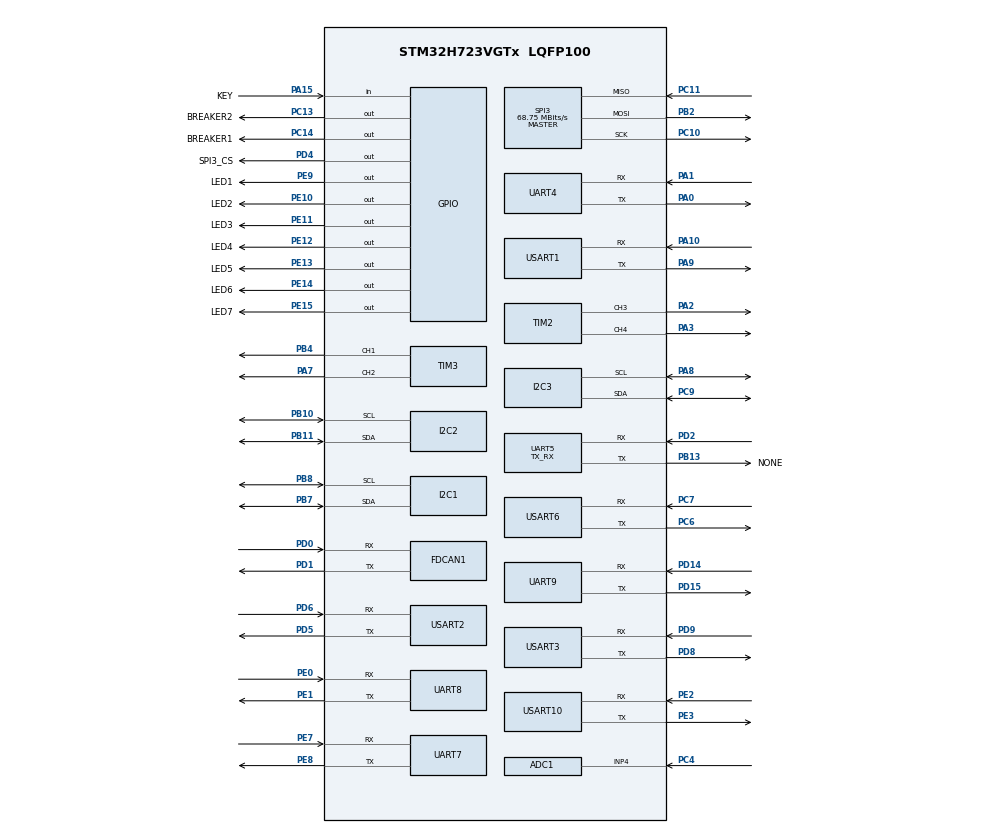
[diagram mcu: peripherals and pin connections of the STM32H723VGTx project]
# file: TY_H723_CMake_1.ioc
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ADC1.Channel-0\#ChannelRegularConversion=ADC_CHANNEL_4
ADC1.NbrOfConversionFlag=1
ADC1.OffsetNumber-0\#ChannelRegularConversion=ADC_OFFSET_NONE
ADC1.OffsetSignedSaturation-0\#ChannelRegularConversion=DISABLE
ADC1.Rank-0\#ChannelRegularConversion=1
ADC1.SamplingTime-0\#ChannelRegularConversion=ADC_SAMPLETIME_1CYCLE_5
ADC1.master=1
CORTEX_M7.MPU_Control=__NULL
CORTEX_M7.default_mode_Activation=0
Dma.Request0=USART1_TX
Dma.Request1=USART6_TX
Dma.Request2=USART1_RX
Dma.Request3=USART6_RX
Dma.Request4=UART9_RX
Dma.Request5=UART9_TX
Dma.UART9_RX.4.Direction=DMA_PERIPH_TO_MEMORY
Dma.UART9_RX.4.EventEnable=DISABLE
Dma.UART9_RX.4.FIFOMode=DMA_FIFOMODE_DISABLE
Dma.UART9_RX.4.Instance=DMA1_Stream4
Dma.UART9_RX.4.MemDataAlignment=DMA_MDATAALIGN_BYTE
Dma.UART9_RX.4.MemInc=DMA_MINC_ENABLE
Dma.UART9_RX.4.Mode=DMA_NORMAL
Dma.UART9_RX.4.PeriphDataAlignment=DMA_PDATAALIGN_BYTE
Dma.UART9_RX.4.PeriphInc=DMA_PINC_DISABLE
Dma.UART9_RX.4.Polarity=HAL_DMAMUX_REQ_GEN_RISING
Dma.UART9_RX.4.Priority=DMA_PRIORITY_LOW
Dma.UART9_RX.4.RequestNumber=1
Dma.UART9_RX.4.SignalID=NONE
Dma.UART9_RX.4.SyncEnable=DISABLE
Dma.UART9_RX.4.SyncPolarity=HAL_DMAMUX_SYNC_NO_EVENT
Dma.UART9_RX.4.SyncRequestNumber=1
Dma.UART9_RX.4.SyncSignalID=NONE
Dma.UART9_TX.5.Direction=DMA_MEMORY_TO_PERIPH
Dma.UART9_TX.5.EventEnable=DISABLE
Dma.UART9_TX.5.FIFOMode=DMA_FIFOMODE_ENABLE
Dma.UART9_TX.5.FIFOThreshold=DMA_FIFO_THRESHOLD_FULL
Dma.UART9_TX.5.Instance=DMA1_Stream5
Dma.UART9_TX.5.MemBurst=DMA_MBURST_SINGLE
Dma.UART9_TX.5.MemDataAlignment=DMA_MDATAALIGN_BYTE
Dma.UART9_TX.5.MemInc=DMA_MINC_ENABLE
Dma.UART9_TX.5.Mode=DMA_NORMAL
Dma.UART9_TX.5.PeriphBurst=DMA_PBURST_SINGLE
Dma.UART9_TX.5.PeriphDataAlignment=DMA_PDATAALIGN_BYTE
Dma.UART9_TX.5.PeriphInc=DMA_PINC_DISABLE
Dma.UART9_TX.5.Polarity=HAL_DMAMUX_REQ_GEN_RISING
Dma.UART9_TX.5.Priority=DMA_PRIORITY_LOW
Dma.UART9_TX.5.RequestNumber=1
Dma.UART9_TX.5.SignalID=NONE
Dma.UART9_TX.5.SyncEnable=DISABLE
Dma.UART9_TX.5.SyncPolarity=HAL_DMAMUX_SYNC_NO_EVENT
Dma.UART9_TX.5.SyncRequestNumber=1
Dma.UART9_TX.5.SyncSignalID=NONE
Dma.USART1_RX.2.Direction=DMA_PERIPH_TO_MEMORY
Dma.USART1_RX.2.EventEnable=DISABLE
Dma.USART1_RX.2.FIFOMode=DMA_FIFOMODE_ENABLE
Dma.USART1_RX.2.FIFOThreshold=DMA_FIFO_THRESHOLD_FULL
Dma.USART1_RX.2.Instance=DMA1_Stream1
Dma.USART1_RX.2.MemBurst=DMA_MBURST_SINGLE
Dma.USART1_RX.2.MemDataAlignment=DMA_MDATAALIGN_BYTE
Dma.USART1_RX.2.MemInc=DMA_MINC_ENABLE
Dma.USART1_RX.2.Mode=DMA_NORMAL
Dma.USART1_RX.2.PeriphBurst=DMA_PBURST_SINGLE
Dma.USART1_RX.2.PeriphDataAlignment=DMA_PDATAALIGN_BYTE
Dma.USART1_RX.2.PeriphInc=DMA_PINC_DISABLE
Dma.USART1_RX.2.Polarity=HAL_DMAMUX_REQ_GEN_RISING
Dma.USART1_RX.2.Priority=DMA_PRIORITY_LOW
Dma.USART1_RX.2.RequestNumber=1
Dma.USART1_RX.2.SignalID=NONE
Dma.USART1_RX.2.SyncEnable=DISABLE
Dma.USART1_RX.2.SyncPolarity=HAL_DMAMUX_SYNC_NO_EVENT
Dma.USART1_RX.2.SyncRequestNumber=1
Dma.USART1_RX.2.SyncSignalID=NONE
Dma.USART1_TX.0.Direction=DMA_MEMORY_TO_PERIPH
Dma.USART1_TX.0.EventEnable=DISABLE
Dma.USART1_TX.0.FIFOMode=DMA_FIFOMODE_ENABLE
Dma.USART1_TX.0.FIFOThreshold=DMA_FIFO_THRESHOLD_FULL
Dma.USART1_TX.0.Instance=DMA1_Stream3
Dma.USART1_TX.0.MemBurst=DMA_MBURST_SINGLE
Dma.USART1_TX.0.MemDataAlignment=DMA_MDATAALIGN_BYTE
Dma.USART1_TX.0.MemInc=DMA_MINC_ENABLE
Dma.USART1_TX.0.Mode=DMA_NORMAL
Dma.USART1_TX.0.PeriphBurst=DMA_PBURST_SINGLE
Dma.USART1_TX.0.PeriphDataAlignment=DMA_PDATAALIGN_BYTE
Dma.USART1_TX.0.PeriphInc=DMA_PINC_DISABLE
Dma.USART1_TX.0.Polarity=HAL_DMAMUX_REQ_GEN_RISING
Dma.USART1_TX.0.Priority=DMA_PRIORITY_LOW
Dma.USART1_TX.0.RequestNumber=1
Dma.USART1_TX.0.SignalID=NONE
Dma.USART1_TX.0.SyncEnable=DISABLE
Dma.USART1_TX.0.SyncPolarity=HAL_DMAMUX_SYNC_NO_EVENT
Dma.USART1_TX.0.SyncRequestNumber=1
Dma.USART1_TX.0.SyncSignalID=NONE
Dma.USART6_RX.3.Direction=DMA_PERIPH_TO_MEMORY
Dma.USART6_RX.3.EventEnable=DISABLE
Dma.USART6_RX.3.FIFOMode=DMA_FIFOMODE_DISABLE
Dma.USART6_RX.3.Instance=DMA1_Stream0
Dma.USART6_RX.3.MemDataAlignment=DMA_MDATAALIGN_BYTE
Dma.USART6_RX.3.MemInc=DMA_MINC_ENABLE
Dma.USART6_RX.3.Mode=DMA_NORMAL
Dma.USART6_RX.3.PeriphDataAlignment=DMA_PDATAALIGN_BYTE
Dma.USART6_RX.3.PeriphInc=DMA_PINC_DISABLE
Dma.USART6_RX.3.Polarity=HAL_DMAMUX_REQ_GEN_RISING
Dma.USART6_RX.3.Priority=DMA_PRIORITY_LOW
Dma.USART6_RX.3.RequestNumber=1
Dma.USART6_RX.3.SignalID=NONE
Dma.USART6_RX.3.SyncEnable=DISABLE
Dma.USART6_RX.3.SyncPolarity=HAL_DMAMUX_SYNC_NO_EVENT
Dma.USART6_RX.3.SyncRequestNumber=1
Dma.USART6_RX.3.SyncSignalID=NONE
Dma.USART6_TX.1.Direction=DMA_MEMORY_TO_PERIPH
Dma.USART6_TX.1.EventEnable=DISABLE
Dma.USART6_TX.1.FIFOMode=DMA_FIFOMODE_ENABLE
Dma.USART6_TX.1.FIFOThreshold=DMA_FIFO_THRESHOLD_FULL
Dma.USART6_TX.1.Instance=DMA1_Stream2
Dma.USART6_TX.1.MemBurst=DMA_MBURST_SINGLE
Dma.USART6_TX.1.MemDataAlignment=DMA_MDATAALIGN_BYTE
Dma.USART6_TX.1.MemInc=DMA_MINC_ENABLE
Dma.USART6_TX.1.Mode=DMA_NORMAL
Dma.USART6_TX.1.PeriphBurst=DMA_PBURST_SINGLE
Dma.USART6_TX.1.PeriphDataAlignment=DMA_PDATAALIGN_BYTE
Dma.USART6_TX.1.PeriphInc=DMA_PINC_DISABLE
Dma.USART6_TX.1.Polarity=HAL_DMAMUX_REQ_GEN_RISING
Dma.USART6_TX.1.Priority=DMA_PRIORITY_LOW
Dma.USART6_TX.1.RequestNumber=1
Dma.USART6_TX.1.SignalID=NONE
Dma.USART6_TX.1.SyncEnable=DISABLE
Dma.USART6_TX.1.SyncPolarity=HAL_DMAMUX_SYNC_NO_EVENT
Dma.USART6_TX.1.SyncRequestNumber=1
Dma.USART6_TX.1.SyncSignalID=NONE
FDCAN1.AutoRetransmission=ENABLE
FDCAN1.CalculateBaudRateNominal=1000000
FDCAN1.CalculateTimeBitNominal=1000
FDCAN1.CalculateTimeQuantumNominal=62.5
FDCAN1.NominalPrescaler=6
FDCAN1.NominalTimeSeg1=11
FDCAN1.NominalTimeSeg2=4
FDCAN1.RxBuffersNbr=0
FDCAN1.RxFifo0ElmtsNbr=4
FDCAN1.RxFifo1ElmtsNbr=0
FDCAN1.StdFiltersNbr=4
FDCAN1.TxFifoQueueElmtsNbr=32
FREERTOS.Tasks01=defaultTask,24,128,_defaultTask,As weak,NULL,Dynamic,NULL,NULL
FREERTOS.configENABLE_FPU=1
FREERTOS.configUSE_NEWLIB_REENTRANT=1
I2C1.Timing=0x60404E72
I2C2.Timing=0x60404E72
I2C3.Timing=0x60404E72
Mcu.Family=STM32H7
Mcu.Name=STM32H723VGTx
Mcu.Package=LQFP100
NVIC.DMA1_Stream0_IRQn=true\:5\:0\:false\:false\:true\:true\:false\:true\:true
NVIC.DMA1_Stream1_IRQn=true\:5\:0\:false\:false\:true\:true\:false\:true\:true
NVIC.DMA1_Stream2_IRQn=true\:5\:0\:false\:false\:true\:true\:false\:true\:true
NVIC.DMA1_Stream3_IRQn=true\:5\:0\:false\:false\:true\:true\:false\:true\:true
NVIC.DMA1_Stream4_IRQn=true\:5\:0\:false\:false\:true\:true\:false\:true\:true
NVIC.DMA1_Stream5_IRQn=true\:5\:0\:false\:false\:true\:true\:false\:true\:true
NVIC.FDCAN1_IT0_IRQn=true\:5\:0\:false\:false\:true\:true\:true\:true\:true
NVIC.PriorityGroup=NVIC_PRIORITYGROUP_4
NVIC.TIM1_UP_IRQn=true\:15\:0\:false\:false\:true\:false\:false\:true\:true
NVIC.TimeBase=TIM1_UP_IRQn
NVIC.TimeBaseIP=TIM1
NVIC.UART9_IRQn=true\:5\:0\:false\:false\:true\:true\:true\:true\:true
NVIC.USART1_IRQn=true\:5\:0\:false\:false\:true\:true\:true\:true\:true
NVIC.USART6_IRQn=true\:5\:0\:false\:false\:true\:true\:true\:true\:true
PA0.Mode=Asynchronous
PA0.Signal=UART4_TX
PA1.Mode=Asynchronous
PA1.Signal=UART4_RX
PA10.Mode=Asynchronous
PA10.Signal=USART1_RX
PA13(JTMS/SWDIO).Mode=Serial_Wire
PA13(JTMS/SWDIO).Signal=DEBUG_JTMS-SWDIO
PA14(JTCK/SWCLK).Mode=Serial_Wire
PA14(JTCK/SWCLK).Signal=DEBUG_JTCK-SWCLK
PA15(JTDI).GPIO_Label=KEY
PA15(JTDI).Signal=GPIO_Input
PA2.Signal=S_TIM2_CH3
PA3.Signal=S_TIM2_CH4
PA7.Signal=S_TIM3_CH2
PA8.Mode=I2C
PA8.Signal=I2C3_SCL
PA9.Mode=Asynchronous
PA9.Signal=USART1_TX
PB10.Mode=I2C
PB10.Signal=I2C2_SCL
PB11.Mode=I2C
PB11.Signal=I2C2_SDA
PB13.GPIO_Label=NONE
PB13.Mode=Asynchronous
PB13.Signal=UART5_TX
PB13.Stacked=true
PB2.Mode=Full_Duplex_Master
PB2.Signal=SPI3_MOSI
PB4(NJTRST).Signal=S_TIM3_CH1
PB5.Signal=FDCAN2_RX
PB6.Signal=FDCAN2_TX
PB7.Mode=I2C
PB7.Signal=I2C1_SDA
PB8.Mode=I2C
PB8.Signal=I2C1_SCL
PC10.Mode=Full_Duplex_Master
PC10.Signal=SPI3_SCK
PC11.Mode=Full_Duplex_Master
PC11.Signal=SPI3_MISO
PC13.GPIO_Label=BREAKER2
PC13.Signal=GPIO_Output
PC14-OSC32_IN.GPIO_Label=BREAKER1
PC14-OSC32_IN.Signal=GPIO_Output
PC4.Signal=ADCx_INP4
PC6.Mode=Asynchronous
PC6.Signal=USART6_TX
PC7.Mode=Asynchronous
PC7.Signal=USART6_RX
PC9.Mode=I2C
PC9.Signal=I2C3_SDA
PD0.Mode=FDCAN_Activate
PD0.Signal=FDCAN1_RX
PD1.Mode=FDCAN_Activate
PD1.Signal=FDCAN1_TX
PD12.Signal=FDCAN3_RX
PD13.Signal=FDCAN3_TX
PD14.Mode=Asynchronous
PD14.Signal=UART9_RX
PD15.Mode=Asynchronous
PD15.Signal=UART9_TX
PD2.Mode=Asynchronous
PD2.Signal=UART5_RX
PD4.GPIO_Label=SPI3_CS
PD4.Signal=GPIO_Output
PD5.Mode=Asynchronous
PD5.Signal=USART2_TX
PD6.Mode=Asynchronous
PD6.Signal=USART2_RX
PD8.Mode=Asynchronous
PD8.Signal=USART3_TX
PD9.Mode=Asynchronous
PD9.Signal=USART3_RX
PE0.Mode=Asynchronous
PE0.Signal=UART8_RX
PE1.Mode=Asynchronous
PE1.Signal=UART8_TX
PE10.GPIO_Label=LED2
PE10.Signal=GPIO_Output
PE11.GPIO_Label=LED3
PE11.Signal=GPIO_Output
PE12.GPIO_Label=LED4
PE12.Signal=GPIO_Output
PE13.GPIO_Label=LED5
PE13.Signal=GPIO_Output
PE14.GPIO_Label=LED6
PE14.Signal=GPIO_Output
PE15.GPIO_Label=LED7
PE15.Signal=GPIO_Output
PE2.Mode=Asynchronous
PE2.Signal=USART10_RX
PE3.Mode=Asynchronous
PE3.Signal=USART10_TX
PE7.Mode=Asynchronous
PE7.Signal=UART7_RX
PE8.Mode=Asynchronous
PE8.Signal=UART7_TX
PE9.GPIO_Label=LED1
PE9.Signal=GPIO_Output
PH0-OSC_IN.Mode=HSE-External-Oscillator
PH0-OSC_IN.Signal=RCC_OSC_IN
PH1-OSC_OUT.Mode=HSE-External-Oscillator
PH1-OSC_OUT.Signal=RCC_OSC_OUT
ProjectManager.HeapSize=0x400
ProjectManager.StackSize=0x400
ProjectManager.TargetToolchain=CMake
RCC.ADCFreq_Value=96000000
RCC.APB1Freq_Value=137500000
RCC.APB2Freq_Value=137500000
RCC.APB3Freq_Value=137500000
RCC.APB4Freq_Value=137500000
RCC.CortexFreq_Value=550000000
RCC.D1PPRE=RCC_APB3_DIV2
RCC.D2PPRE1=RCC_APB1_DIV2
RCC.D2PPRE2=RCC_APB2_DIV2
RCC.D3PPRE=RCC_APB4_DIV2
RCC.DIVM1=4
RCC.DIVM2=4
RCC.DIVN1=34
RCC.DIVN2=12
RCC.DIVP1=1
RCC.DIVQ1=4
RCC.FDCANCLockSelection=RCC_FDCANCLKSOURCE_PLL2
RCC.HCLKFreq_Value=275000000
RCC.HPRE=RCC_HCLK_DIV2
RCC.HSE_VALUE=24000000
RCC.PLL1_VCI_Range-AdvancedSettings=RCC_PLL1VCIRANGE_0
RCC.PLL1_VCO_SEL-AdvancedSettings=RCC_PLL1VCOMEDIUM
RCC.PLL2FRACN=0
RCC.PLL2_VCI_Range-AdvancedSettings=RCC_PLL2VCIRANGE_0
RCC.PLL2_VCO_SEL-AdvancedSettings=RCC_PLL2VCOMEDIUM
RCC.PLL3FRACN=0
RCC.PLL3_VCI_Range-AdvancedSettings=RCC_PLL3VCIRANGE_1
RCC.PLL3_VCO_SEL-AdvancedSettings=RCC_PLL3VCOWIDE
RCC.PLLFRACN=3072
RCC.SYSCLKFreq_VALUE=550000000
RCC.SYSCLKSource=RCC_SYSCLKSOURCE_PLLCLK
RCC.USBFreq_Value=137500000
SH.ADCx_INP4.0=ADC1_INP4,IN4-Single-Ended
SH.S_TIM2_CH3.0=TIM2_CH3,PWM Generation3 CH3
SH.S_TIM2_CH4.0=TIM2_CH4,PWM Generation4 CH4
SH.S_TIM3_CH1.0=TIM3_CH1,PWM Generation1 CH1
SH.S_TIM3_CH2.0=TIM3_CH2,PWM Generation2 CH2
SPI3.CalculateBaudRate=68.75 MBits/s
SPI3.Direction=SPI_DIRECTION_2LINES
SPI3.Mode=SPI_MODE_MASTER
SPI3.VirtualType=VM_MASTER
TIM2.Channel-PWM\ Generation3\ CH3=TIM_CHANNEL_3
TIM2.Channel-PWM\ Generation4\ CH4=TIM_CHANNEL_4
TIM3.Channel-PWM\ Generation1\ CH1=TIM_CHANNEL_1
TIM3.Channel-PWM\ Generation2\ CH2=TIM_CHANNEL_2
UART5.Mode=MODE_TX_RX
USART1.VirtualMode-Asynchronous=VM_ASYNC
USART10.VirtualMode=VM_ASYNC
USART2.FIFOMode=FIFOMODE_DISABLE
USART2.VirtualMode-Asynchronous=VM_ASYNC
USART3.VirtualMode-Asynchronous=VM_ASYNC
USART6.VirtualMode=VM_ASYNC
VP_FREERTOS_VS_CMSIS_V2.Mode=CMSIS_V2
VP_MEMORYMAP_VS_MEMORYMAP.Mode=CurAppReg
VP_SYS_VS_tim1.Mode=TIM1
board=custom

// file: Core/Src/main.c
/* USER CODE BEGIN Header */
/**
  ******************************************************************************
  * @file           : main.c
  * @brief          : Main program body
  ******************************************************************************
  * @attention
  *
  * Copyright (c) 2026 STMicroelectronics.
  * All rights reserved.
  *
  * This software is licensed under terms that can be found in the LICENSE file
  * in the root directory of this software component.
  * If no LICENSE file comes with this software, it is provided AS-IS.
  *
  ******************************************************************************
  */
/* USER CODE END Header */
#include "main.h"
#include "FreeRTOS.h"
#include "cmsis_os2.h"
#include "adc.h"
#include "dma.h"
#include "fdcan.h"
#include "i2c.h"
#include "spi.h"
#include "tim.h"
#include "usart.h"
#include "gpio.h"

/* USER CODE BEGIN Includes */
#include "api_main.h"
/* USER CODE END Includes */

void SystemClock_Config(void);
void PeriphCommonClock_Config(void);
void MX_FREERTOS_Init(void);

int main(void)
{

  /* MCU Configuration--------------------------------------------------------*/

  /* Reset of all peripherals, Initializes the Flash interface and the Systick. */
  HAL_Init();

  /* Configure the system clock */
  SystemClock_Config();

  /* Configure the peripherals common clocks */
  PeriphCommonClock_Config();

  /* Initialize all configured peripherals */
  MX_GPIO_Init();
  MX_DMA_Init();
  MX_ADC1_Init();
  MX_FDCAN1_Init();
  MX_I2C1_Init();
  MX_I2C2_Init();
  MX_I2C3_Init();
  MX_SPI3_Init();
  MX_TIM2_Init();
  MX_TIM3_Init();
  MX_UART4_Init();
  MX_UART5_Init();
  MX_UART7_Init();
  MX_UART8_Init();
  MX_UART9_Init();
  MX_USART1_UART_Init();
  MX_USART2_UART_Init();
  MX_USART3_UART_Init();
  MX_USART6_UART_Init();
  MX_USART10_UART_Init();
  /* USER CODE BEGIN 2 */
  app_init();
  /* USER CODE END 2 */

  /* Init scheduler */
  osKernelInitialize();  /* Call init function for freertos objects (in cmsis_os2.c) */
  MX_FREERTOS_Init();

  /* Start scheduler */
  osKernelStart();

  /* We should never get here as control is now taken by the scheduler */

  /* Infinite loop */
  while (1)
  {

  }
}

void SystemClock_Config(void)
{
  RCC_OscInitTypeDef RCC_OscInitStruct = {0};
  RCC_ClkInitTypeDef RCC_ClkInitStruct = {0};

  /** Supply configuration update enable
  */
  HAL_PWREx_ConfigSupply(PWR_LDO_SUPPLY);

  /** Configure the main internal regulator output voltage
  */
  __HAL_PWR_VOLTAGESCALING_CONFIG(PWR_REGULATOR_VOLTAGE_SCALE0);

  while(!__HAL_PWR_GET_FLAG(PWR_FLAG_VOSRDY)) {}

  /** Initializes the RCC Oscillators according to the specified parameters
  * in the RCC_OscInitTypeDef structure.
  */
  RCC_OscInitStruct.OscillatorType = RCC_OSCILLATORTYPE_HSI;
  RCC_OscInitStruct.HSIState = RCC_HSI_DIV1;
  RCC_OscInitStruct.HSICalibrationValue = 64;
  RCC_OscInitStruct.PLL.PLLState = RCC_PLL_ON;
  RCC_OscInitStruct.PLL.PLLSource = RCC_PLLSOURCE_HSI;
  RCC_OscInitStruct.PLL.PLLM = 4;
  RCC_OscInitStruct.PLL.PLLN = 34;
  RCC_OscInitStruct.PLL.PLLP = 1;
  RCC_OscInitStruct.PLL.PLLQ = 4;
  RCC_OscInitStruct.PLL.PLLR = 2;
  RCC_OscInitStruct.PLL.PLLRGE = RCC_PLL1VCIRANGE_3;
  RCC_OscInitStruct.PLL.PLLVCOSEL = RCC_PLL1VCOWIDE;
  RCC_OscInitStruct.PLL.PLLFRACN = 3072;
  if (HAL_RCC_OscConfig(&RCC_OscInitStruct) != HAL_OK)
  {
    Error_Handler();
  }

  /** Initializes the CPU, AHB and APB buses clocks
  */
  RCC_ClkInitStruct.ClockType = RCC_CLOCKTYPE_HCLK|RCC_CLOCKTYPE_SYSCLK
                              |RCC_CLOCKTYPE_PCLK1|RCC_CLOCKTYPE_PCLK2
                              |RCC_CLOCKTYPE_D3PCLK1|RCC_CLOCKTYPE_D1PCLK1;
  RCC_ClkInitStruct.SYSCLKSource = RCC_SYSCLKSOURCE_PLLCLK;
  RCC_ClkInitStruct.SYSCLKDivider = RCC_SYSCLK_DIV1;
  RCC_ClkInitStruct.AHBCLKDivider = RCC_HCLK_DIV2;
  RCC_ClkInitStruct.APB3CLKDivider = RCC_APB3_DIV2;
  RCC_ClkInitStruct.APB1CLKDivider = RCC_APB1_DIV2;
  RCC_ClkInitStruct.APB2CLKDivider = RCC_APB2_DIV2;
  RCC_ClkInitStruct.APB4CLKDivider = RCC_APB4_DIV2;

  if (HAL_RCC_ClockConfig(&RCC_ClkInitStruct, FLASH_LATENCY_3) != HAL_OK)
  {
    Error_Handler();
  }
}

void PeriphCommonClock_Config(void)
{
  RCC_PeriphCLKInitTypeDef PeriphClkInitStruct = {0};

  /** Initializes the peripherals clock
  */
  PeriphClkInitStruct.PeriphClockSelection = RCC_PERIPHCLK_ADC|RCC_PERIPHCLK_FDCAN;
  PeriphClkInitStruct.PLL2.PLL2M = 4;
  PeriphClkInitStruct.PLL2.PLL2N = 12;
  PeriphClkInitStruct.PLL2.PLL2P = 2;
  PeriphClkInitStruct.PLL2.PLL2Q = 2;
  PeriphClkInitStruct.PLL2.PLL2R = 2;
  PeriphClkInitStruct.PLL2.PLL2RGE = RCC_PLL2VCIRANGE_3;
  PeriphClkInitStruct.PLL2.PLL2VCOSEL = RCC_PLL2VCOWIDE;
  PeriphClkInitStruct.PLL2.PLL2FRACN = 0;
  PeriphClkInitStruct.FdcanClockSelection = RCC_FDCANCLKSOURCE_PLL2;
  PeriphClkInitStruct.AdcClockSelection = RCC_ADCCLKSOURCE_PLL2;
  if (HAL_RCCEx_PeriphCLKConfig(&PeriphClkInitStruct) != HAL_OK)
  {
    Error_Handler();
  }
}

void HAL_TIM_PeriodElapsedCallback(TIM_HandleTypeDef *htim)
{
  if (htim->Instance == TIM1)
  {
    HAL_IncTick();
  }
}

void Error_Handler(void)
{
  __disable_irq();
  while (1)
  {
  }
}

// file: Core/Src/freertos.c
/* USER CODE BEGIN Header */
/**
  ******************************************************************************
  * File Name          : freertos.c
  * Description        : Code for freertos applications
  ******************************************************************************
  * @attention
  *
  * Copyright (c) 2026 STMicroelectronics.
  * All rights reserved.
  *
  * This software is licensed under terms that can be found in the LICENSE file
  * in the root directory of this software component.
  * If no LICENSE file comes with this software, it is provided AS-IS.
  *
  ******************************************************************************
  */
/* USER CODE END Header */

#include "FreeRTOS.h"
#include "task.h"
#include "main.h"
#include "FreeRTOS.h"
#include "cmsis_os2.h"

/* USER CODE BEGIN Includes */
#include <stdio.h>
#include "api_main.h"
/* USER CODE END Includes */

/* Definitions for defaultTask */
osThreadId_t defaultTaskHandle;
const osThreadAttr_t defaultTask_attributes = {
  .name = "defaultTask",
  .stack_size = 128 * 4,
  .priority = (osPriority_t) osPriorityNormal,
};

void _defaultTask(void *argument);

void MX_FREERTOS_Init(void); /* (MISRA C 2004 rule 8.1) */

void MX_FREERTOS_Init(void) {
  /* USER CODE BEGIN Init */
  freertos_init();
  /* USER CODE END Init */

  /* Create the thread(s) */
  /* creation of defaultTask */
  defaultTaskHandle = osThreadNew(_defaultTask, NULL, &defaultTask_attributes);

}

__weak void _defaultTask(void *argument)
{
  for(;;)
  {
    osDelay(1);
  }
}
